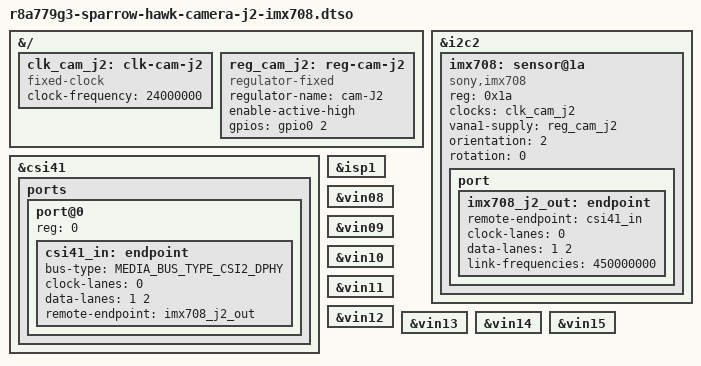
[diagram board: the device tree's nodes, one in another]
// SPDX-License-Identifier: (GPL-2.0-only OR BSD-2-Clause)
/*
 * Device Tree Overlay for an IMX219 camera sensor on connector J2 on R-Car V4H
 * ES3.0 Sparrow Hawk board.
 *
 * Copyright 2025 Ideas On Board Oy
 * Author: Jacopo Mondi <jacopo.mondi@ideasonboard.com>
 */

/dts-v1/;
/plugin/;

#include <dt-bindings/gpio/gpio.h>
#include <dt-bindings/media/video-interfaces.h>

&{/} {
	clk_cam_j2: clk-cam-j2 {
		compatible = "fixed-clock";
		#clock-cells = <0>;
		clock-frequency = <24000000>;
	};

	/* Page 29 / CSI_IF_CN / J2 */
	reg_cam_j2: reg-cam-j2 {
		compatible = "regulator-fixed";
		regulator-name = "cam-J2";
		enable-active-high;
		gpios = <&gpio0 2 GPIO_ACTIVE_HIGH>;
	};
};

&i2c2 {
	#address-cells = <1>;
	#size-cells = <0>;
	status = "okay";

	imx708: sensor@1a {
		compatible = "sony,imx708";
		reg = <0x1a>;
		status = "okay";

		clocks = <&clk_cam_j2>;
		clock-names = "inclk";

		vana1-supply = <&reg_cam_j2>;

		orientation = <2>;
		rotation = <0>;

		port {
			imx708_j2_out: endpoint {
				remote-endpoint = <&csi41_in>;
				clock-lanes = <0>;
				data-lanes = <1 2>;
				link-frequencies = /bits/ 64 <450000000>;
			};
		};
	};
};

/* Page 29 / CSI_IF_CN */
&csi41 {
	status = "okay";

	ports {
		#address-cells = <1>;
		#size-cells = <0>;

		port@0 {
			reg = <0>;

			csi41_in: endpoint {
				bus-type = <MEDIA_BUS_TYPE_CSI2_DPHY>;
				clock-lanes = <0>;
				data-lanes = <1 2>;
				remote-endpoint = <&imx708_j2_out>;
			};
		};
	};
};

&isp1 {
	status = "okay";
};

&vin08 {
	status = "okay";
};

&vin09 {
	status = "okay";
};

&vin10 {
	status = "okay";
};

&vin11 {
	status = "okay";
};

&vin12 {
	status = "okay";
};

&vin13 {
	status = "okay";
};

&vin14 {
	status = "okay";
};

&vin15 {
	status = "okay";
};
